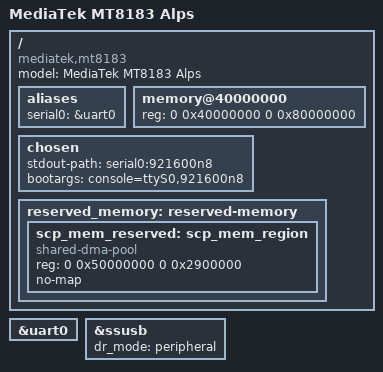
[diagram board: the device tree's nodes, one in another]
// SPDX-License-Identifier: (GPL-2.0 OR MIT)
/*
 * Device tree for MediaTek MT8183 Alps board (Android tablet bring-up).
 * Minimal early-boot set: gic/sysirq/timer/clk syscons come from mt8183.dtsi
 * (default okay), only uart0 console is enabled here. UFS / display / touch
 * are added in later stages.
 */

/dts-v1/;
#include "mt8183.dtsi"
#include "mt8183-alps-fixup.dtsi"

/ {
	model = "MediaTek MT8183 Alps";
	compatible = "mediatek,mt8183";

	aliases {
		serial0 = &uart0;
	};

	memory@40000000 {
		device_type = "memory";
		reg = <0 0x40000000 0 0x80000000>;
	};

	chosen: chosen {
		stdout-path = "serial0:921600n8";
		bootargs = "console=ttyS0,921600n8";
	};

	reserved_memory: reserved-memory {
		#address-cells = <2>;
		#size-cells = <2>;
		ranges;
		scp_mem_reserved: scp_mem_region {
			compatible = "shared-dma-pool";
			reg = <0 0x50000000 0 0x2900000>;
			no-map;
		};
	};
};

&uart0 {
	status = "okay";
};

&ssusb {
	status = "okay";
	dr_mode = "peripheral";
};
